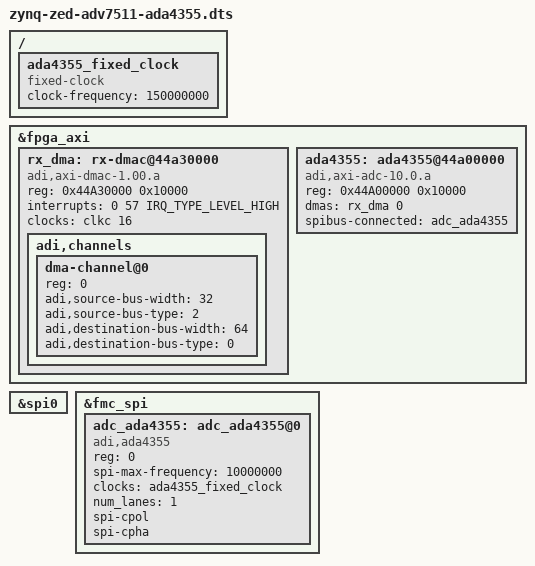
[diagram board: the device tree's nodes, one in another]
// SPDX-License-Identifier: GPL-2.0
/*
 * Analog Devices ad4080
 *
 * hdl_project: <ada4355_fmc/zed>
 * board_revision: <>
 *
 * Copyright (C) 2025 Analog Devices Inc.
 */
/dts-v1/;

#include "zynq-zed.dtsi"
#include "zynq-zed-adv7511.dtsi"

&fpga_axi {
	rx_dma: rx-dmac@44a30000 {
		compatible = "adi,axi-dmac-1.00.a";
		reg = <0x44A30000 0x10000>;
		#dma-cells = <1>;
		interrupts = <0 57 IRQ_TYPE_LEVEL_HIGH>;
		clocks = <&clkc 16>; // fclk 1 in zynq-7000

		adi,channels {
			#size-cells = <0>;
			#address-cells = <1>;

			dma-channel@0 {
				reg = <0>;
				adi,source-bus-width = <32>;
				adi,source-bus-type = <2>;
				adi,destination-bus-width = <64>;
				adi,destination-bus-type = <0>;
			};
		};
	};

    ada4355: ada4355@44a00000 {
	        compatible = "adi,axi-adc-10.0.a";
	        reg = <0x44A00000 0x10000>;
	        dmas = <&rx_dma 0>;
	        dma-names = "rx";

	        spibus-connected = <&adc_ada4355>;
    };
};

&spi0 {
	status = "okay";
};


#define fmc_spi spi0

/ {
    ada4355_fixed_clock: ada4355_fixed_clock{
        compatible = "fixed-clock";
        #clock-cells = <0>;
        clock-frequency = <150000000>;
    };
};

&fmc_spi {
	adc_ada4355: adc_ada4355@0 {
		compatible = "adi,ada4355";
		reg = <0>;
		spi-max-frequency = <10000000>;
		//clocks = <&clkc 16>;
        clocks = <&ada4355_fixed_clock>;
		clock-names = "adc_clk";
		num_lanes = <1>;
        spi-cpol;
        spi-cpha;
	};

};

